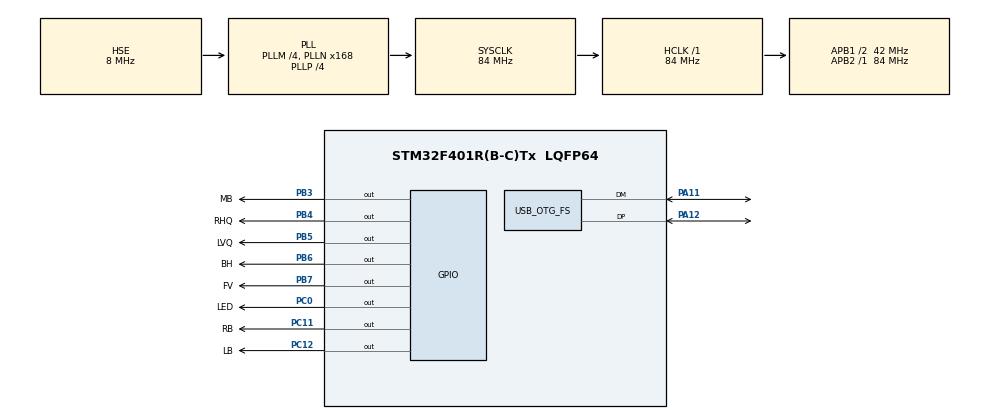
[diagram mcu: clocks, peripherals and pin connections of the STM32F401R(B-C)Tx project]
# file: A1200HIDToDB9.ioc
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Mcu.Family=STM32F4
Mcu.Name=STM32F401R(B-C)Tx
Mcu.Package=LQFP64
NVIC.OTG_FS_IRQn=true\:0\:0\:false\:false\:true\:false\:true
NVIC.PriorityGroup=NVIC_PRIORITYGROUP_4
NVIC.RCC_IRQn=true\:0\:0\:false\:false\:true\:true\:false
NVIC.TIM1_UP_TIM10_IRQn=true\:15\:0\:false\:false\:true\:false\:true
NVIC.TIM2_IRQn=true\:0\:0\:false\:false\:true\:true\:true
NVIC.TIM3_IRQn=true\:0\:0\:false\:false\:true\:true\:true
NVIC.TimeBase=TIM1_UP_TIM10_IRQn
NVIC.TimeBaseIP=TIM10
PA11.Mode=Host_Only
PA11.Signal=USB_OTG_FS_DM
PA12.Mode=Host_Only
PA12.Signal=USB_OTG_FS_DP
PB3.GPIO_Label=MB
PB3.Signal=GPIO_Output
PB4.GPIO_Label=RHQ
PB4.Signal=GPIO_Output
PB5.GPIO_Label=LVQ
PB5.Signal=GPIO_Output
PB6.GPIO_Label=BH
PB6.Signal=GPIO_Output
PB7.GPIO_Label=FV
PB7.Signal=GPIO_Output
PC0.GPIO_Label=LED
PC0.Signal=GPIO_Output
PC11.GPIO_Label=RB
PC11.Signal=GPIO_Output
PC12.GPIO_Label=LB
PC12.Signal=GPIO_Output
PH0\ -\ OSC_IN.Mode=HSE-External-Oscillator
PH0\ -\ OSC_IN.Signal=RCC_OSC_IN
PH1\ -\ OSC_OUT.Mode=HSE-External-Oscillator
PH1\ -\ OSC_OUT.Signal=RCC_OSC_OUT
ProjectManager.HeapSize=0x2000
ProjectManager.StackSize=0x2000
ProjectManager.TargetToolchain=STM32CubeIDE
RCC.48MHZClocksFreq_Value=48000000
RCC.AHBFreq_Value=84000000
RCC.APB1CLKDivider=RCC_HCLK_DIV2
RCC.APB1Freq_Value=42000000
RCC.APB1TimFreq_Value=84000000
RCC.APB2Freq_Value=84000000
RCC.APB2TimFreq_Value=84000000
RCC.CortexFreq_Value=84000000
RCC.HCLKFreq_Value=84000000
RCC.HSE_Timout=1000
RCC.HSE_VALUE=8000000
RCC.HSI_VALUE=16000000
RCC.LSE_VALUE=32768
RCC.PLLM=4
RCC.PLLN=168
RCC.PLLP=RCC_PLLP_DIV4
RCC.PLLQ=7
RCC.PWR_Regulator_Voltage_Scale=PWR_REGULATOR_VOLTAGE_SCALE3
RCC.SYSCLKFreq_VALUE=84000000
RCC.SYSCLKSource=RCC_SYSCLKSOURCE_PLLCLK
RCC.VCOOutputFreq_Value=336000000
TIM2.Period=1000
TIM2.Prescaler=5376-1
TIM3.Period=1000
TIM3.Prescaler=5376-1
USB_HOST.USBH_HandleTypeDef=hUsbHostFS
USB_HOST.VirtualModeFS=Hid
USB_OTG_FS.VirtualMode=Host_Only
USB_OTG_FS.phy_itface=HCD_PHY_EMBEDDED
VP_SYS_VS_tim10.Mode=TIM10
VP_TIM2_VS_ClockSourceINT.Mode=Internal
VP_TIM3_VS_ClockSourceINT.Mode=Internal
VP_USB_HOST_VS_USB_HOST_HID_FS.Mode=HID_FS
board=custom

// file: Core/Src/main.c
/* USER CODE BEGIN Header */
/**
  ******************************************************************************
  * @file           : main.c
  * @brief          : Main program body
  ******************************************************************************
  * @attention
  *
  * Copyright (c) 2021 STMicroelectronics.
  * All rights reserved.
  *
  * This software is licensed under terms that can be found in the LICENSE file
  * in the root directory of this software component.
  * If no LICENSE file comes with this software, it is provided AS-IS.
  *
  ******************************************************************************
  */
/* USER CODE END Header */
#include "main.h"
#include "tim.h"
#include "usb_host.h"
#include "gpio.h"

void SystemClock_Config(void);
void MX_USB_HOST_Process(void);

int main(void)
{

  /* MCU Configuration--------------------------------------------------------*/

  /* Reset of all peripherals, Initializes the Flash interface and the Systick. */
  HAL_Init();

  /* Configure the system clock */
  SystemClock_Config();

  /* Initialize all configured peripherals */
  MX_GPIO_Init();
  MX_USB_HOST_Init();
  MX_TIM2_Init();
  MX_TIM3_Init();
  /* USER CODE BEGIN 2 */
  HAL_TIM_Base_Start_IT(&htim2) ;
  HAL_TIM_Base_Start_IT(&htim3) ;
  /* USER CODE END 2 */

  /* Infinite loop */
  while (1)
  {
    MX_USB_HOST_Process();

    /* USER CODE BEGIN 3 */
    ProcessMouse();
    ProcessJoystick();
  }
  /* USER CODE END 3 */
}

void SystemClock_Config(void)
{
  RCC_OscInitTypeDef RCC_OscInitStruct = {0};
  RCC_ClkInitTypeDef RCC_ClkInitStruct = {0};

  /** Configure the main internal regulator output voltage
  */
  __HAL_RCC_PWR_CLK_ENABLE();
  __HAL_PWR_VOLTAGESCALING_CONFIG(PWR_REGULATOR_VOLTAGE_SCALE3);
  /** Initializes the RCC Oscillators according to the specified parameters
  * in the RCC_OscInitTypeDef structure.
  */
  RCC_OscInitStruct.OscillatorType = RCC_OSCILLATORTYPE_HSE;
  RCC_OscInitStruct.HSEState = RCC_HSE_ON;
  RCC_OscInitStruct.PLL.PLLState = RCC_PLL_ON;
  RCC_OscInitStruct.PLL.PLLSource = RCC_PLLSOURCE_HSE;
  RCC_OscInitStruct.PLL.PLLM = 4;
  RCC_OscInitStruct.PLL.PLLN = 168;
  RCC_OscInitStruct.PLL.PLLP = RCC_PLLP_DIV4;
  RCC_OscInitStruct.PLL.PLLQ = 7;
  if (HAL_RCC_OscConfig(&RCC_OscInitStruct) != HAL_OK)
  {
    Error_Handler();
  }
  /** Initializes the CPU, AHB and APB buses clocks
  */
  RCC_ClkInitStruct.ClockType = RCC_CLOCKTYPE_HCLK|RCC_CLOCKTYPE_SYSCLK
                              |RCC_CLOCKTYPE_PCLK1|RCC_CLOCKTYPE_PCLK2;
  RCC_ClkInitStruct.SYSCLKSource = RCC_SYSCLKSOURCE_PLLCLK;
  RCC_ClkInitStruct.AHBCLKDivider = RCC_SYSCLK_DIV1;
  RCC_ClkInitStruct.APB1CLKDivider = RCC_HCLK_DIV2;
  RCC_ClkInitStruct.APB2CLKDivider = RCC_HCLK_DIV1;

  if (HAL_RCC_ClockConfig(&RCC_ClkInitStruct, FLASH_LATENCY_2) != HAL_OK)
  {
    Error_Handler();
  }
}

void HAL_TIM_PeriodElapsedCallback(TIM_HandleTypeDef *htim)
{
  if (htim->Instance == TIM10) {
    HAL_IncTick();
  }
  /* USER CODE BEGIN Callback 1 */

  if (htim->Instance == TIM2) {
   ProcessX_IRQ();
  }

  if (htim->Instance == TIM3) {
	  ProcessY_IRQ();
  }

  /* USER CODE END Callback 1 */
}

void Error_Handler(void)
{
  __disable_irq();
  while (1)
  {
  }
}
